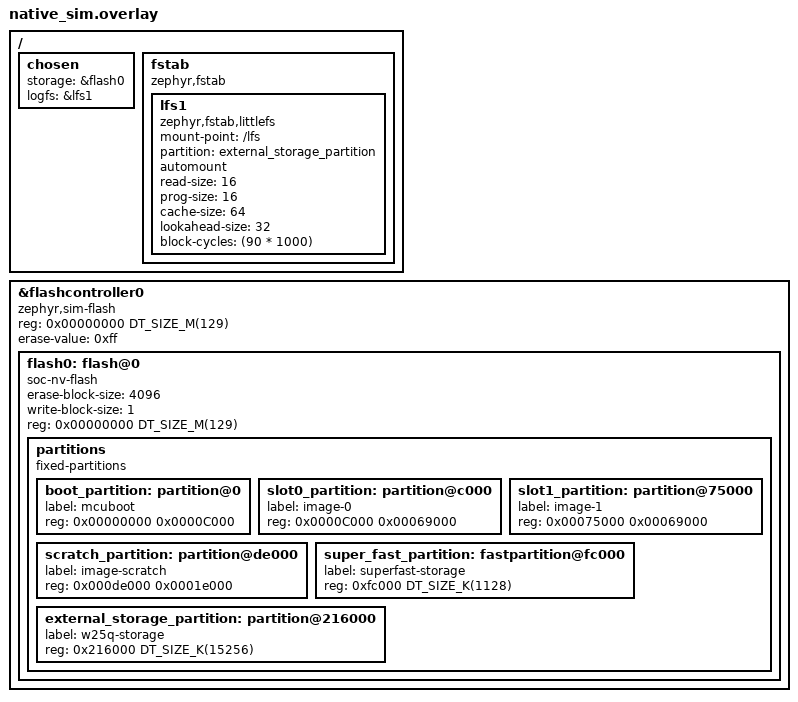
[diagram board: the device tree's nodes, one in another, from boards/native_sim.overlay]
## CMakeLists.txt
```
cmake_minimum_required(VERSION 3.20.0)

find_package(Zephyr REQUIRED HINTS $ENV{ZEPHYR_BASE})

include(${ZEPHYR_FSW_MODULE_DIR}/cmake/Autocoders.cmake)


project(payload_flight_software LANGUAGES CXX)

target_compile_options(app PRIVATE -Wall -Wno-unused-parameter -Wno-unused-function -Wno-ignored-qualifiers)
FILE(GLOB app_sources src/*.cpp src/*.c)
target_sources(app PRIVATE ${app_sources})

AutocodeTypes(${CMAKE_SOURCE_DIR}/ac/types.yaml)
AutocodeNetworkDefinitions()
add_dependencies(app ac_types)
```

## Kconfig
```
source "Kconfig.zephyr"

config STORAGE_THREAD_STACK_SIZE
    int "Stack size for storage size"
    default 512

config STORAGE_THREAD_PRIORITY
    int "Stack size for storage size"
    default 10

config SLOWDATA_THREAD_STACK_SIZE
    int "Stack size for storage size"
    default 512

config SLOWDATA_THREAD_PRIORITY
    int "Stack size for storage size"
    default 10

config HORUS_PAYLOAD_ID
    int "Payload ID number as given by horusdemodlib"
    default 808

config HORUS_TIMESLOT_SECONDS
    int "Number of seconds between the start of transmissions (30 -> transmit every thirty seconds)"
    default 10

config HORUS_TIMESLOT_OFFSET_SECONDS
    int "Number of seconds off the start of the 0th hour to start transmitting (5 -> start at 12:00:05 and transmit every HORUS_TIMESLOT_SECONDS)"
    default 5

module = APP_FREAK
module-str = APP_FREAK
source "subsys/logging/Kconfig.template.log_config"
```

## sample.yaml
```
sample:
  description: Control Freak flight software
  name: control_freak
common:
  build_only: true
  platform_allow:
    - control_freak
tests:
  control_freak.flight.default: {}
```

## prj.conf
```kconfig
CONFIG_DEBUG=y
CONFIG_THREAD_NAME=y
CONFIG_DEBUG_THREAD_INFO=y

CONFIG_THREAD_ANALYZER=y
CONFIG_THREAD_ANALYZER_USE_PRINTK=y
CONFIG_THREAD_ANALYZER_AUTO=y
CONFIG_THREAD_ANALYZER_AUTO_INTERVAL=15

CONFIG_HORUS_TIMESLOT_SECONDS=15
CONFIG_HORUS_TIMESLOT_OFFSET_SECONDS=0

# default 99 but boostdata lock needs to happen after and 
# zephyr dies if priority > 99
CONFIG_FILE_SYSTEM_INIT_PRIORITY=98
CONFIG_CPP=y
CONFIG_REQUIRES_FULL_LIBCPP=y
CONFIG_STD_CPP20=y

CONFIG_F_CORE=y
CONFIG_F_CORE_OS=y

CONFIG_MAIN_STACK_SIZE=8192


# CONFIG_NO_OPTIMIZATIONS=y
CONFIG_SPEED_OPTIMIZATIONS=y
CONFIG_REBOOT=y

CONFIG_LOG=y
CONFIG_APP_FREAK_LOG_LEVEL_INF=y
CONFIG_CBPRINTF_FP_SUPPORT=y
CONFIG_LOG_PRINTK=y
CONFIG_SHELL_LOG_BACKEND=y

CONFIG_POLL=y
CONFIG_BASE64=y
CONFIG_SERIAL=y
CONFIG_SPI=y
CONFIG_I2C=y


CONFIG_EVENTS=y

#CONFIG_UART_ASYNC_API=y
CONFIG_UART_CONSOLE=y
# CONFIG_SHELL_BACKEND_UART=y
# 
# CONFIG_UART_CONSOLE=n
# CONFIG_RTT_CONSOLE=y
# CONFIG_USE_SEGGER_RTT=y
# CONFIG_SHELL_BACKEND_RTT=y
# CONFIG_UART_INTERRUPT_DRIVEN=y

CONFIG_SHELL=y

CONFIG_GPIO_SHELL=y
CONFIG_I2C_SHELL=y
CONFIG_SENSOR_SHELL=y
CONFIG_FLASH_SHELL=y
CONFIG_FILE_SYSTEM_SHELL=y
CONFIG_HEAP_MEM_POOL_SIZE=8192

# Flash chip is SPI
CONFIG_FLASH=y
CONFIG_FLASH_MAP=y
CONFIG_FLASH_PAGE_LAYOUT=y

# Use filesystem
CONFIG_FILE_SYSTEM=y
# Use LittleFS as the filesystem
CONFIG_FILE_SYSTEM_LITTLEFS=y
# LittleFS is mounted on a flash map device
CONFIG_FS_LITTLEFS_FMP_DEV=y 




CONFIG_SENSOR=y
CONFIG_SENSOR_INFO=y

CONFIG_PWM=y

CONFIG_LORA=y
CONFIG_LORA_SHELL=y
CONFIG_LORA_SX127X=y
#CONFIG_LORA_LOG_LEVEL_DBG=y
CONFIG_HORUSV2=y
CONFIG_HORUS_LOG_LEVEL_WRN=y

CONFIG_GNSS=y
CONFIG_GNSS_SATELLITES=n
CONFIG_GNSS_LOG_LEVEL_INF=y

#CONFIG_GNSS_DUMP_TO_LOG=y
#CONFIG_GNSS_DUMP_TO_LOG_BUF_SIZE=1024

CONFIG_SYSTEM_WORKQUEUE_STACK_SIZE=8096
CONFIG_FLASH_SHELL_BUFFER_SIZE=1024

CONFIG_SHELL_STACK_SIZE=4096
CONFIG_STORAGE_THREAD_STACK_SIZE=1536
CONFIG_LOG_BUFFER_SIZE=4096
```

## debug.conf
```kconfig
CONFIG_DEBUG=y
CONFIG_THREAD_NAME=y
CONFIG_DEBUG_THREAD_INFO=y

CONFIG_THREAD_ANALYZER=y
CONFIG_THREAD_ANALYZER_USE_PRINTK=y
CONFIG_THREAD_ANALYZER_AUTO=y
CONFIG_THREAD_ANALYZER_AUTO_INTERVAL=5
```

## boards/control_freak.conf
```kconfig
CONFIG_SPI_NOR_SLEEP_WHILE_WAITING_UNTIL_READY=y
# sector erase time typical is 45ms
CONFIG_SPI_NOR_SLEEP_ERASE_MS=20

CONFIG_CORTEX_M_SYSTICK_64BIT_CYCLE_COUNTER=y
CONFIG_DMA=y
CONFIG_SPI_STM32_DMA=y

CONFIG_I2C_STM32_BUS_RECOVERY=y
# Actual Devices
CONFIG_GNSS=y
CONFIG_U_BLOX_M10=y

CONFIG_LORA=y
CONFIG_LORA_SX127X=y



CONFIG_SENSOR=y
CONFIG_LSM6DSL=y
CONFIG_BMP388=y
CONFIG_INA260=y
```

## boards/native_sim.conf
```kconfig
CONFIG_GPIO_EMUL=y
CONFIG_FLASH_SIMULATOR=y
CONFIG_GPIO=y
CONFIG_LED=y
CONFIG_FLASH=y
CONFIG_FLASH_SIMULATOR_SIMULATE_TIMING=y
CONFIG_FLASH_SIMULATOR_DOUBLE_WRITES=y
CONFIG_ASAN=y
```

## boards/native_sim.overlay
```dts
/ {
	chosen {
		storage = &flash0;
		logfs = &lfs1;
	};


	fstab {
		compatible = "zephyr,fstab";
		lfs1: lfs1 {
			compatible = "zephyr,fstab,littlefs";
			mount-point = "/lfs";
			partition = <&external_storage_partition>;
			automount;

			// the binding reccomends defaults for these
			read-size = <16>;
			prog-size = <16>;
			cache-size = <64>; // may need to grow for optimization
			lookahead-size = <32>;
			block-cycles = <(90 * 1000)>;
			// the datasheet gives 100K P-E cycles
			// NOTE: this seems to default to 512 for the mounted filesystem
			// anyway
		};
	};

};

&flashcontroller0 {
	status = "okay";
	compatible = "zephyr,sim-flash";
	reg = <0x00000000 DT_SIZE_M(129)>;

	#address-cells = <1>;
	#size-cells = <1>;
	erase-value = <0xff>;

	flash0: flash@0 {
		status = "okay";
		compatible = "soc-nv-flash";
		erase-block-size = <4096>;
		write-block-size = <1>;
		reg = <0x00000000 DT_SIZE_M(129)>; // builtin stuff + external flash simulation

		partitions {
			compatible = "fixed-partitions";
			#address-cells = <1>;
			#size-cells = <1>;

			boot_partition: partition@0 {
				label = "mcuboot";
				reg = <0x00000000 0x0000C000>;
			};
			slot0_partition: partition@c000 {
				label = "image-0";
				reg = <0x0000C000 0x00069000>;
			};
			slot1_partition: partition@75000 {
				label = "image-1";
				reg = <0x00075000 0x00069000>;
			};
			scratch_partition: partition@de000 {
				label = "image-scratch";
				reg = <0x000de000 0x0001e000>;
			};
			
			
			super_fast_partition: fastpartition@fc000 {
				// loop(5s * 100 page/s) + (400s * 10 page/s)
				// 4500 pages = 1125 KB
				label = "superfast-storage";
				reg = <0xfc000 DT_SIZE_K(1128)>;
			};

			external_storage_partition: partition@216000 {
				label = "w25q-storage";
				reg = <0x216000 DT_SIZE_K(15256)>;
			};
		};
	};
};
```

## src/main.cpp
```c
#include "5v_ctrl.h"
#include "boost.h"
#include "buzzer.h"
#include "cameras.h"
#include "common.h"
#include "cycle_counter.hpp"
#include "f_core/os/c_datalogger.h"
#include "fast_sensing.h"
#include "flight.h"
#include "flipping.h"
#include "gorbfs.h"
#include "gps.h"
#include "slow_sensing.h"
#include "storage.h"

#include <zephyr/drivers/gnss.h>
#include <zephyr/drivers/sensor.h>
#include <zephyr/logging/log.h>
#include <zephyr/logging/log_ctrl.h>
#include <zephyr/shell/shell.h>
#include <zephyr/sys/base64.h>
#include <zephyr/sys/reboot.h>
LOG_MODULE_REGISTER(main, CONFIG_APP_FREAK_LOG_LEVEL);

#include <zephyr/kernel.h>

static constexpr float BATTERY_WARNING_THRESH = 7.9;
float startup_voltage = 0;

extern struct k_msgq flightlog_msgq;
void handler(FreakFlightController::EventNotification noti) { k_msgq_put(&flightlog_msgq, &noti, K_MSEC(1)); }

FreakFlightController freak_controller{sourceNames, eventNames, timerEvents, decisionFuncs, handler};
static const struct device *superfast_storage = DEVICE_DT_GET(DT_NODE_BY_FIXED_PARTITION_LABEL(superfast_storage));
static const struct device *superslow_storage = DEVICE_DT_GET(DT_NODE_BY_FIXED_PARTITION_LABEL(superslow_storage));
static const struct device *superyev_storage = DEVICE_DT_GET(DT_NODE_BY_FIXED_PARTITION_LABEL(superyev_storage));

Partitions parts{
    .superfast_dev = superfast_storage,
    .superslow_dev = superslow_storage,
    .superyev_dev = superyev_storage,
};

int radio_thread(void *, void *, void *);
K_THREAD_DEFINE(radio, 4096, radio_thread, (void *) &freak_controller, (void *) &superfast_storage, NULL,
                CONFIG_STORAGE_THREAD_PRIORITY, 0, 0);

K_THREAD_DEFINE(storage, CONFIG_STORAGE_THREAD_STACK_SIZE, storage_thread_entry, (void *) &freak_controller,
                (void *) &parts, NULL, CONFIG_STORAGE_THREAD_PRIORITY, 0, 0);

K_THREAD_DEFINE(slow_sensing, CONFIG_SLOWDATA_THREAD_STACK_SIZE, slow_sensing_thread, (void *) &freak_controller, NULL,
                NULL, CONFIG_SLOWDATA_THREAD_PRIORITY, 0, 0);

K_THREAD_DEFINE(cameras, 512, camera_thread_entry, (void *) &freak_controller, NULL, NULL,
                CONFIG_SLOWDATA_THREAD_PRIORITY, 0, 0);

K_THREAD_DEFINE(buzzer, 512, buzzer_entry_point, NULL, NULL, NULL, CONFIG_SLOWDATA_THREAD_PRIORITY, 0, 0);

int main() {
    int ret = 0;
    if (is_data_locked()) {
        buzzer_tell(BuzzCommand::DataLocked);
        return -1;
    }
    ret = five_volt_rail_init();
    if (ret != 0) {
        LOG_ERR("Failed to init 5v rail control");
        buzzer_tell(BuzzCommand::SensorTroubles);
    }

    const struct device *imu_dev = DEVICE_DT_GET(DT_ALIAS(imu));
    const struct device *barom_dev = DEVICE_DT_GET(DT_ALIAS(barom));

    const struct device *ina_servo = DEVICE_DT_GET(DT_ALIAS(inaservo));
    const struct device *ina_pump = DEVICE_DT_GET(DT_ALIAS(inapump));

    if (!device_is_ready(imu_dev) || !device_is_ready(barom_dev)) {
        LOG_ERR("Sensor devices not ready");
        buzzer_tell(BuzzCommand::SensorTroubles);
        return -1;
    }
    if (!device_is_ready(ina_servo) || !device_is_ready(ina_pump)) {
        LOG_ERR("Sensor devices not ready");
        buzzer_tell(BuzzCommand::SensorTroubles);
        return -1;
    }
    float current = 0;
    ret = read_ina(ina_servo, startup_voltage, current);
    if (ret != 0) {
        LOG_ERR("Couldn't read battery");
    }
    if (startup_voltage < BATTERY_WARNING_THRESH) {
        buzzer_tell(BuzzCommand::BatteryWarning);
    }

    if (!device_is_ready(superfast_storage)) {
        LOG_ERR("Storage not ready");
        buzzer_tell(BuzzCommand::SensorTroubles);
    }

    ret = init_flip_hw();
    if (ret != 0) {
        LOG_ERR("Error initializing servo hardware");
        buzzer_tell(BuzzCommand::SensorTroubles);
    }

    buzzer_tell(BuzzCommand::AllGood);

    //Ground, Boost, Coast, Flight
    ret = boost_and_flight_sensing(superfast_storage, imu_dev, barom_dev, ina_servo, &freak_controller);
    LOG_INF("On the ground now");

    do_flipping_and_pumping(imu_dev, barom_dev, ina_servo, ina_pump);
    LOG_WRN("you really shouldnt be here");

    return 0;
}

int cmd_pumpon(const struct shell *shell, size_t argc, char **argv) {
    shell_print(shell, "pump on");
    rail_item_enable(FiveVoltItem::Pump);
    return 0;
}

int cmd_pumpoff(const struct shell *shell, size_t argc, char **argv) {
    shell_print(shell, "pump off");
    rail_item_disable(FiveVoltItem::Pump);
    return 0;
}

int cmd_unlock(const struct shell *shell, size_t argc, char **argv) {
    shell_print(shell, "Unlocking boost data");
    unlock_boostdata();
    buzzer_tell(BuzzCommand::AllGood);
    return 0;
}

int cmd_lock(const struct shell *shell, size_t argc, char **argv) {
    shell_print(shell, "Locking boost data");
    lock_boostdata();
    return 0;
}

int cmd_stop(const struct shell *shell, size_t argc, char **argv);

int cmd_shutup(const struct shell *shell, size_t argc, char **argv) {
    shell_print(shell, "Acknowledging that you dont care that data is locked");
    buzzer_tell(BuzzCommand::AllGood);
    return 0;
}

extern bool overriding_boost;
int cmd_boost(const struct shell *shell, size_t argc, char **argv) {
    shell_print(shell, "Boost");
    overriding_boost = true;
    return 0;
}
int cmd_preflight(const struct shell *shell, size_t argc, char **argv) {
    shell_print(shell, "Preflight Checklist");
    shell_print(shell, "Cameras on");
    shell_print(shell, "Startup Voltage: %.3f", (double) startup_voltage);
    if (startup_voltage < BATTERY_WARNING_THRESH) {
        LOG_ERR("BATTERY LOW");
        buzzer_tell(BuzzCommand::BatteryWarning);
    }
    both_cams_on();
    servo_preflight(shell);
    shell_print(shell, "Check Cameras");
    k_msleep(10 * 1000);
    shell_print(shell, "Cameras off");
    both_cams_off();

    return 0;
}
int cmd_info(const struct shell *shell, size_t argc, char **argv) {
    print_gps();
    return 0;
}

int hexdump(const struct shell *shell, uint8_t *buf, size_t size) {
    for (size_t i = 0; i < size; i++) {
        shell_fprintf_normal(shell, "%02X", buf[i]);
        if (i % 32 == 31 && i != 0) {
            shell_print(shell, "");
        }
    }

    return 0;
}

// dump base64 data here before printing
#define DUMP_BUFFER_LEN (256 * 2)
uint8_t dumping_data[DUMP_BUFFER_LEN + 1];

static int b64dump(const struct shell *shell, uint8_t *buf) {
    int ret;
    size_t num_written = 0;
    ret = base64_encode(dumping_data, DUMP_BUFFER_LEN, &num_written, buf, 256);
    if (ret < 0) {
        shell_print(shell, "encoding error %d, num_written: %d of 256", ret, num_written);
        return ret;
    }
    dumping_data[DUMP_BUFFER_LEN] = 0; // null terminator
    shell_print(shell, "%s", dumping_data);
    return 0;
}

int cmd_read(const struct device *dev, const struct shell *shell, size_t argc, char **argv) {
    int blocks = gfs_total_blocks(dev);
    if (argc == 1) {

    } else if (argc == 2) {
        int num_blocks = atoi(argv[1]);
        if (num_blocks == 0) {
            shell_error(shell, "Error parsing number or 0 blocks requested");
            return -1;
        }
        if (num_blocks > blocks) {
            shell_error(shell, "Cant read %d blocks of %d", num_blocks, blocks);
            return -1;
        }
        blocks = num_blocks;

    } else {
        shell_error(shell, "I want one argument, number of blocks or none to read the whole partition");
        return -1;
    }
    // b64 dump in 256 byte lines: 500 blocks in 36.51 sec
    shell_print(shell, "************ gorb start %s ************", dev->name);
    static uint8_t buf[256] = {0};
    for (int i = 0; i < blocks; i++) {
        gfs_read_block(dev, i, buf);
        hexdump(shell, buf, 256); // TODO investigate b64 slowdown time
    }
    shell_print(shell, "************ gorb end %s ************", dev->name);
    return 0;
}

int cmd_read_compress(const struct device *dev, const struct shell *shell, size_t argc, char **argv) {
    int blocks = gfs_total_blocks(dev);
    if (argc == 1) {

    } else if (argc == 2) {
        int num_blocks = atoi(argv[1]);
        if (num_blocks == 0) {
            shell_error(shell, "Error parsing number or 0 blocks requested");
            return -1;
        }
        if (num_blocks > blocks) {
            shell_error(shell, "Cant read %d blocks of %d", num_blocks, blocks);
            return -1;
        }
        blocks = num_blocks;

    } else {
        shell_error(shell, "I want one argument, number of blocks or none to read the whole partition");
        return -1;
    }
    // b64 dump in 256 byte lines: 500 blocks in 36.51 sec
    // hexdump 500 blocks in 25.56
    shell_print(shell, "************ gorb start %s ************", dev->name);
    static uint8_t buf[256] = {0};
    for (int i = 0; i < blocks; i++) {
        gfs_read_block(dev, i, buf);
        hexdump(shell, buf, 256);
    }
    shell_print(shell, "************ gorb end %s ************", dev->name);
    return 0;
}

int cmd_readfast(const struct shell *shell, size_t argc, char **argv) {
    return cmd_read(superfast_storage, shell, argc, argv);
}
int cmd_readslow(const struct shell *shell, size_t argc, char **argv) {
    return cmd_read(superslow_storage, shell, argc, argv);
}

SHELL_STATIC_SUBCMD_SET_CREATE(freak_subcmds, SHELL_CMD(stop, NULL, "Stop Test", cmd_stop),
                               SHELL_CMD(unlock, NULL, "Unlock flight data partition", cmd_unlock),
                               SHELL_CMD(lock, NULL, "Lock flight data partition", cmd_lock),
                               SHELL_CMD(moduleon, NULL, "pump on", cmd_pumpon),
                               SHELL_CMD(moduleoff, NULL, "pump off", cmd_pumpoff),
                               SHELL_CMD(info, NULL, "freak info", cmd_info),
                               SHELL_CMD(boost, NULL, "fake boost detect", cmd_boost),
                               SHELL_CMD(preflight, NULL, "run preflight checks", cmd_preflight),
                               SHELL_CMD(shut, NULL, "stop yapping", cmd_shutup), SHELL_SUBCMD_SET_END);

SHELL_CMD_REGISTER(freak, &freak_subcmds, "Test Commands", NULL);

SHELL_STATIC_SUBCMD_SET_CREATE(gorb_subcmds, SHELL_CMD(dumpfast, NULL, "Dump fast partition", cmd_readfast),
                               SHELL_CMD(dumpslow, NULL, "Dump slow partition", cmd_readslow), SHELL_SUBCMD_SET_END);

SHELL_CMD_REGISTER(gorb, &gorb_subcmds, "Gorbfs Commands", NULL);
```

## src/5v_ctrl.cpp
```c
#include "5v_ctrl.h"

#include <initializer_list>
#include <tuple>
#include <zephyr/drivers/gpio.h>
#include <zephyr/logging/log.h>
LOG_MODULE_REGISTER(rail5v);

static const struct gpio_dt_spec ldo_en = GPIO_DT_SPEC_GET(DT_ALIAS(ldo5v), gpios);

static const struct gpio_dt_spec servo_en = GPIO_DT_SPEC_GET(DT_NODELABEL(servo_enable), gpios);

static const struct gpio_dt_spec pump_enable = GPIO_DT_SPEC_GET(DT_NODELABEL(pump_enable), gpios);

const struct gpio_dt_spec buzzer = GPIO_DT_SPEC_GET(DT_ALIAS(buzz), gpios);

// Prepares the GPIO
int five_volt_rail_init() {
    using Pair = std::tuple<const struct gpio_dt_spec *, const char *>;
    constexpr Pair pairs[4] = {
        Pair{&ldo_en, "ldo5v"},
        Pair{&servo_en, "servo"},
        Pair{&pump_enable, "pump"},
        Pair{&buzzer, "buzzer"},
    };
    for (auto [gpio, name] : pairs) {
        if (!gpio_is_ready_dt(gpio)) {
            LOG_WRN("No %s pin :(", name);
        }
        int ret = gpio_pin_configure_dt(gpio, GPIO_OUTPUT_INACTIVE);
        if (ret < 0) {
            LOG_WRN("Failed to conf %s pin:(", name);
            return ret;
        }
    }
    LOG_INF("5V Rail all good");
    return 0;
}

static bool state[(int) FiveVoltItem::NumItems] = {false};

static int set_ldo_accordingly() { return gpio_pin_set_dt(&ldo_en, (state[0] || state[1] || state[2])); }
static int set_item(FiveVoltItem item, bool set) {
    if (item >= FiveVoltItem::NumItems) {
        LOG_WRN("Invalid 5v rail item");
        return -ENODEV;
    }
    state[(int) item] = set;
    if (item == FiveVoltItem::Buzzer) {
        return gpio_pin_set_dt(&buzzer, set);
    } else if (item == FiveVoltItem::Servos) {
        return gpio_pin_set_dt(&servo_en, set);
    } else {
        return gpio_pin_set_dt(&pump_enable, set);
    }
    return 0;
}
// CONFIG_PM who?
int rail_item_enable(FiveVoltItem item) { return rail_item_set(item, true); }

int rail_item_disable(FiveVoltItem item) { return rail_item_set(item, false); }

int rail_item_set(FiveVoltItem item, bool set) {
#if 0
#warning "Buzzer is fake"
    if (item == FiveVoltItem::Buzzer) {
        set_item(item, false);
        return set_ldo_accordingly();
    }
#endif
    set_item(item, set);
    return set_ldo_accordingly();
}
```

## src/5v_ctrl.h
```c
#pragma once
#include <cstdint>

enum class FiveVoltItem : uint8_t { Buzzer = 0, Servos = 1, Pump = 2, NumItems = 3 };
/*
5V Bus looks like this

                    +-- Servo Logic Shifter Enable---Servo Logic Shifters
VBAT---LDO Enable---+--       Buzzer Enable       ---Buzzer
                    +--       Pump Enable         ---Pump

The LDO draws a fair amount of current when running even when things downstream are off
This file allows controlling individual elements and automatically handling the LDO Enable pin 
*/

// Prepares the GPIO
int five_volt_rail_init();

// enable a zone (if everything else is off, turn the rail on)
int rail_item_enable(FiveVoltItem item);

// disable a zone (if everything else is off, turn the rail off)
int rail_item_disable(FiveVoltItem item);

// change the state of a zone
int rail_item_set(FiveVoltItem item, bool state);
```

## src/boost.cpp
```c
#include "boost.h"

#include "buzzer.h"
#include "f_core/utils/linear_fit.hpp"
#include "flight.h"

#include <cmath>
#include <zephyr/kernel.h>

// we sample at 1000hz, how convenient
CMovingAverage<float, imuBoostTimeThreshold> acc_buf{0};

bool overriding_boost = false;
// Dummy easu
bool feed_boost_acc(k_ticks_t ts_ticks, const NTypes::AccelerometerData &xyz) {
    float mag_sqrd = xyz.X * xyz.X + xyz.Y * xyz.Y + xyz.Z * xyz.Z;
    acc_buf.Feed(mag_sqrd);
    // imuBoostThresholdMPerS2 * imuBoostThresholdMPerS2

#if 1
    static constexpr float boost_thresh = 2 * 9.8 * 9.8;
#warning "FAKE BOOST DETECT"
#else
    static constexpr float boost_thresh = imuBoostThresholdMPerS2 * imuBoostThresholdMPerS2;
#endif
    if (acc_buf.Avg() > boost_thresh) {
        printk("Boosted fr\n");
        buzzer_tell(BuzzCommand::AllGood);
        return true;
    }
    if (overriding_boost) {
        printk("Boosted not fr\n");
        buzzer_tell(BuzzCommand::AllGood);
        return true;
    }
    return false;
}
bool feed_boost_barom(int64_t ts_us, float temp, float press) { return false; }
```

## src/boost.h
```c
#pragma once

#include "common.h"

#include <stdbool.h>
#include <stdint.h>
#include <zephyr/kernel.h>

bool feed_boost_acc(k_ticks_t ts_ticks, const NTypes::AccelerometerData&);
bool feed_boost_barom(int64_t ts_us, float temp, float press);
```

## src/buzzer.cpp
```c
#include "buzzer.h"

#include "5v_ctrl.h"

#include <zephyr/device.h>
#include <zephyr/drivers/gpio.h>
#include <zephyr/kernel.h>
#include <zephyr/logging/log.h>
LOG_MODULE_REGISTER(buzzer);

K_MSGQ_DEFINE(buzzer_msgq, sizeof(BuzzCommand), 4, 1);

void buzzer_entry_point(void *, void *, void *);
void buzzer_tell(BuzzCommand cond) { k_msgq_put(&buzzer_msgq, &cond, K_MSEC(10)); }

/*
 * Each bit corresponds to 1/8th of a second. a 1 means the buzzer is going
 * and a 0 means the buzzer is silent
 * After a code is beeped out, it is followed by 2 seconds of silence to differentiate messages
*/

#define BEEPCODE_LENGTH 32

const uint32_t beepcodes[] = {
    [Silent] = 0b00000000000000000000000000000000,
#if 0
#warning "INCORRECT BUZZER"
    [AllGood] = 0b10000000000000000000000000000000,
#else
    [AllGood] = 0b11111111111111111111111100000000,
#endif
    [SensorTroubles] = 0b11000000000000000000000000000000, [BatteryWarning] = 0b1110001110001110001110000000000,
    [BatteryBad] = 0b1110001110001110000000000000000,      [DataLocked] = 0b10101010101010101010101010101010,
};

// whether or not to continue beeping after one go
const bool beepcodes_continue[] = {
    [Silent] = false,        // doesnt really matter
    [AllGood] = false,       // say once then shut up
    [SensorTroubles] = true, // condition to scrub
    [BatteryWarning] = true, // condition to scrub
    [BatteryBad] = true,     // condition to scrub
    [DataLocked] = true,     // condition to scrub
};

void buzzer_entry_point(void *, void *, void *) {
    uint32_t frame = 0;
    BuzzCommand current_cond = BuzzCommand::Silent;
    uint32_t current_code = beepcodes[current_cond];
    bool needs_continue = true;
    bool continue_mask = true;
    while (true) {
        // Read new buzzer request
        BuzzCommand incoming;
        if (k_msgq_get(&buzzer_msgq, &incoming, K_NO_WAIT) == 0) {
            current_cond = incoming;
            current_code = beepcodes[current_cond];
            needs_continue = beepcodes_continue[current_cond];
            continue_mask = true;
            frame = 0;
        }
        // Set buzzer according to beepcode
        int buzzer_state = (current_code >> frame) & 0b1;
        rail_item_set(FiveVoltItem::Buzzer, buzzer_state && continue_mask);

        // Progress time and wrap around when needed
        frame++;
        if (frame >= BEEPCODE_LENGTH) {
            frame = 0;
            if (!needs_continue) {
                continue_mask = false;
            }
        }
        k_msleep(125);
    }
    return;
}
```

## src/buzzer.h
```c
#pragma once
void buzzer_entry_point(void *, void *, void *);

enum BuzzCommand {
    Silent,
    AllGood,
    SensorTroubles,
    BatteryWarning,
    BatteryBad,
    DataLocked,

};
void buzzer_tell(enum BuzzCommand bc);
```

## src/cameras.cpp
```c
#include "flight.h"

#include <zephyr/drivers/gpio.h>
#include <zephyr/logging/log.h>
#include <zephyr/shell/shell.h>

LOG_MODULE_REGISTER(cameras);

static constexpr uint32_t millis_off = (15 * 60 * 1000);
static constexpr uint32_t millis_on = (40 * 1000);
static constexpr float no_cam_voltage_thresshold = 7.9;

static float last_battery_voltage = 8.0;

int update_battery_voltage(const float &bat_voltage);
bool should_turnon_cam() { return last_battery_voltage > no_cam_voltage_thresshold; }

int camera_on(const struct gpio_dt_spec *cam) { return gpio_pin_set_dt(cam, 1); }
int camera_off(const struct gpio_dt_spec *cam) { return gpio_pin_set_dt(cam, 0); }

static const struct gpio_dt_spec antenna_cam = GPIO_DT_SPEC_GET(DT_ALIAS(antennacam), gpios);
static const struct gpio_dt_spec ground_cam = GPIO_DT_SPEC_GET(DT_ALIAS(antennacam), gpios);

void both_cams_on() {
    camera_on(&antenna_cam);
    camera_on(&ground_cam);
}
void both_cams_off() {
    camera_off(&antenna_cam);
    camera_off(&ground_cam);
}

int camera_thread_entry(void *v_fc, void *, void *) {
    FreakFlightController *fc = static_cast<FreakFlightController *>(v_fc);

    int ret = gpio_pin_configure_dt(&antenna_cam, GPIO_OUTPUT);
    if (ret != 0) {
        LOG_WRN("Couldnt configure antennacam");
    }
    ret = gpio_pin_configure_dt(&ground_cam, GPIO_OUTPUT);
    if (ret != 0) {
        LOG_WRN("Couldnt configure antennacam");
    }

    camera_off(&antenna_cam);
    camera_off(&ground_cam);

    fc->WaitUntilEvent(Events::Boost);

    camera_on(&antenna_cam);
    camera_on(&ground_cam);
    LOG_INF("Both cameras on");

    fc->WaitUntilEvent(Events::InitialInflation);
    k_msleep(10 * 60 * 1000);
    camera_off(&antenna_cam);
    camera_off(&antenna_cam);
    LOG_INF("All cam off");

    return 0;
}

int cmd_upcam(const struct shell *shell, size_t argc, char **argv) {
    if (argc != 2) {
        shell_error(shell, "Need 0 or 1 to turn on or off");
        return -1;
    }
    bool turnon = false;
    if (argv[1][0] == '1') {
        turnon = true;
    } else if (argv[1][0] == '0') {
        turnon = false;
    } else {
        shell_error(shell, "Couldnt parse second arg");
        return -1;
    }
    if (turnon) {
        return camera_on(&antenna_cam);
    } else {
        return camera_off(&antenna_cam);
    }
}

int cmd_downcam(const struct shell *shell, size_t argc, char **argv) {
    if (argc != 2) {
        shell_error(shell, "Need 0 or 1 to turn on or off");
        return -1;
    }
    bool turnon = false;
    if (argv[1][0] == '1') {
        turnon = true;
    } else if (argv[1][0] == '0') {
        turnon = false;
    } else {
        shell_error(shell, "Couldnt parse second arg");
        return -1;
    }
    if (turnon) {
        return camera_on(&ground_cam);
    } else {
        return camera_off(&ground_cam);
    }
}

SHELL_STATIC_SUBCMD_SET_CREATE(cam_subcmds, SHELL_CMD(up, NULL, "Up Camera 0/1", cmd_upcam),
                               SHELL_CMD(down, NULL, "Down Camera 0/1", cmd_downcam), SHELL_SUBCMD_SET_END);
SHELL_CMD_REGISTER(cam, &cam_subcmds, "Camera Commands", NULL);
```

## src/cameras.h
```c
#pragma once
int camera_thread_entry(void *v_fc, void *, void *);

void both_cams_on();
void both_cams_off();

int update_battery_voltage(const float &bat_voltage);
```

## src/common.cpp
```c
#include "common.h"

#include <cmath>
#include <zephyr/drivers/sensor.h>
#include <zephyr/fs/fs.h>

int read_ina(const struct device *ina_dev, float &voltage, float &current) {

    struct sensor_value value;
    int ret = sensor_sample_fetch(ina_dev);
    if (ret != 0) {
        return ret;
    }
    sensor_channel_get(ina_dev, SENSOR_CHAN_CURRENT, &value);
    current = sensor_value_to_float(&value);
    if (current > 78) {
        // man the EEs gotta be missing something
        current = 0;
    }

    sensor_channel_get(ina_dev, SENSOR_CHAN_VOLTAGE, &value);
    voltage = sensor_value_to_float(&value);
    return 0;
}

int read_barom(const struct device *barom_dev, float &temp, float &press) {
    int ret = sensor_sample_fetch(barom_dev);
    if (ret != 0) {
        return ret;
    }
    struct sensor_value val;
    sensor_channel_get(barom_dev, SENSOR_CHAN_PRESS, &val);
    press = sensor_value_to_float(&val);

    sensor_channel_get(barom_dev, SENSOR_CHAN_AMBIENT_TEMP, &val);
    temp = sensor_value_to_float(&val);
    return 0;
}

int read_imu(const struct device *imu_dev, NTypes::AccelerometerData &acc, NTypes::GyroscopeData &gyro) {
    int ret = sensor_sample_fetch(imu_dev);
    if (ret != 0) {
        return ret;
    }
    struct sensor_value vals[3];
    ret = sensor_channel_get(imu_dev, SENSOR_CHAN_ACCEL_XYZ, vals);
    if (ret != 0) {
        return ret;
    }
    acc.X = sensor_value_to_float(&vals[0]);
    acc.Y = sensor_value_to_float(&vals[1]);
    acc.Z = sensor_value_to_float(&vals[2]);

    ret = sensor_channel_get(imu_dev, SENSOR_CHAN_GYRO_XYZ, vals);
    if (ret != 0) {
        return ret;
    }
    gyro.X = sensor_value_to_float(&vals[0]);
    gyro.Y = sensor_value_to_float(&vals[1]);
    gyro.Z = sensor_value_to_float(&vals[2]);
    return 0;
}

int set_lsm_sampling(const struct device *imu_dev, int odr) {
    struct sensor_value sampling = {0};
    sensor_value_from_float(&sampling, odr);
    int ret = sensor_attr_set(imu_dev, SENSOR_CHAN_ACCEL_XYZ, SENSOR_ATTR_SAMPLING_FREQUENCY, &sampling);
    if (ret < 0) {
        printk("LSM6DSL: Couldnt set accel sampling\n");
        return ret;
    }
    ret = sensor_attr_set(imu_dev, SENSOR_CHAN_GYRO_XYZ, SENSOR_ATTR_SAMPLING_FREQUENCY, &sampling);
    if (ret < 0) {
        printk("LSM6DSL: Couldnt set gyro sampling\n");
        return ret;
    }
    return 0;
}

NTypes::AccelerometerData normalize(NTypes::AccelerometerData acc) {
    float magn = sqrtf(acc.X * acc.X + acc.Y * acc.Y + acc.Z * acc.Z);
    return {acc.X / magn, acc.Y / magn, acc.Z / magn};
}

extern bool boostdata_locked;
static struct fs_file_t allowfile;

bool is_data_locked() { return boostdata_locked; }

// Needed for sys init (seemingly)
extern "C" {
int init_boostdata_locked() {
    printk("\nChecking boostdata lock\n");
    fs_file_t_init(&allowfile);
    fs_dirent ent = {};
    int ret = fs_stat(ALLOWFILE_PATH, &ent);
    if (ret != 0) {
        printk("No allowfile found, locked!\n\n");
        boostdata_locked = true;
        return -1;
    } else {
        printk("Allowfile found, flash unlocked\n\n");
        boostdata_locked = false;
        return 0;
    }
}
}
#define DATA_LOCK_PRIORITY 99
static_assert(DATA_LOCK_PRIORITY > CONFIG_FILE_SYSTEM_INIT_PRIORITY, "Relies on FS");
SYS_INIT(init_boostdata_locked, POST_KERNEL, DATA_LOCK_PRIORITY);

small_orientation minify_orientation(const NTypes::AccelerometerData &normed) {
    small_orientation orientation = {0};
    orientation.x = normed.X * 127;
    orientation.y = normed.Y * 127;
    orientation.z = normed.Z * 127;
    return orientation;
}
```

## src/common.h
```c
#pragma once

#include "n_autocoder_types.h"

#include <stdbool.h>
#include <stdint.h>
#include <zephyr/device.h>

enum class FlightState : uint8_t {
    NotSet = 0,
    OnPad = 1,
    Boost = 2,
    Flight = 3,
    InitialRoll = 4,
    InitialPump = 5,
    Continuous = 6,

};

enum DataLockMsg {
    Lock,
    Unlock,
};

struct YevData {
    uint32_t ms;
    float altitude;
    float velocity;
    float acceleration;
};

#define GNC_PACKETS_PRE_BLOCK 16
struct YevPacket {
    YevData data[GNC_PACKETS_PRE_BLOCK];
};

typedef uint8_t FlipState;
#define FLIP_STATE_NOT_TRYING 0xff

#define FLIP_STATE(current_face, attempts) (((current_face & 0b111) << 5) | (attempts > 30 ? 30 : attempts))

#define IMU_SAMPLES_PER_PACKET                                                                                         \
    (sizeof(((NTypes::SuperFastPacket *) 0)->GyroData) / sizeof(((NTypes::SuperFastPacket *) 0)->GyroData[0]))

#define SLOW_DATA_PER_PACKET 8
using SuperSlowPacket = NTypes::SlowInfo[SLOW_DATA_PER_PACKET];

/**
 * @param ina_dev ina device
 * @param[out] voltage voltage that was read or unchanged on error
 * @param[out] current current that was read or unchanged on error
 */
int read_ina(const struct device *ina_dev, float &voltage, float &current);

int read_imu(const struct device *imu_dev, NTypes::AccelerometerData &acc, NTypes::GyroscopeData &gyro);
int read_barom(const struct device *barom_dev, float &temp, float &press);

int set_lsm_sampling(const struct device *imu_dev, int odr);

NTypes::AccelerometerData normalize(NTypes::AccelerometerData acc);

// If the file exists, you're good to write
// If the file doesn't exist, consider the flash locked
#define ALLOWFILE_PATH "/lfs/good_to_write"
bool is_data_locked();

// implemented by flash thread
void unlock_boostdata();
void lock_boostdata();

// implemented by horus
struct small_orientation {
    int8_t x;
    int8_t y;
    int8_t z;
};

/**
 * @param normalized orientation vector
 * will be very bad if not orientated
 */
small_orientation minify_orientation(const NTypes::AccelerometerData &normed);

int submit_horus_data(const float &tempC, const float &press, const float &batteryVoltage,
                      const small_orientation &orientation, const FlightState &fs);
```

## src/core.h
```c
#include "f_core/radio/protocols/horus/horus.h"

#include <zephyr/kernel.h>

horus_packet_v2 get_telemetry();
bool has_fix();

// thing to get clock drift
float estimate_clock_skew();

k_ticks_t ticks_till_next_timeslot();
```

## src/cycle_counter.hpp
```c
#pragma once
#include <cstdint>
#include <zephyr/kernel.h>

class CycleCounter {
  public:
    CycleCounter(int64_t &toAdd) : toAdd(toAdd) { start_cyc = k_cycle_get_64(); }
    ~CycleCounter() { toAdd += k_cycle_get_64() - start_cyc; }

    CycleCounter(CycleCounter &&) = delete;
    CycleCounter(const CycleCounter &) = delete;
    CycleCounter &operator=(CycleCounter &&) = delete;
    CycleCounter &operator=(const CycleCounter &) = delete;

  private:
    int64_t &toAdd;
    int64_t start_cyc;
};
```
